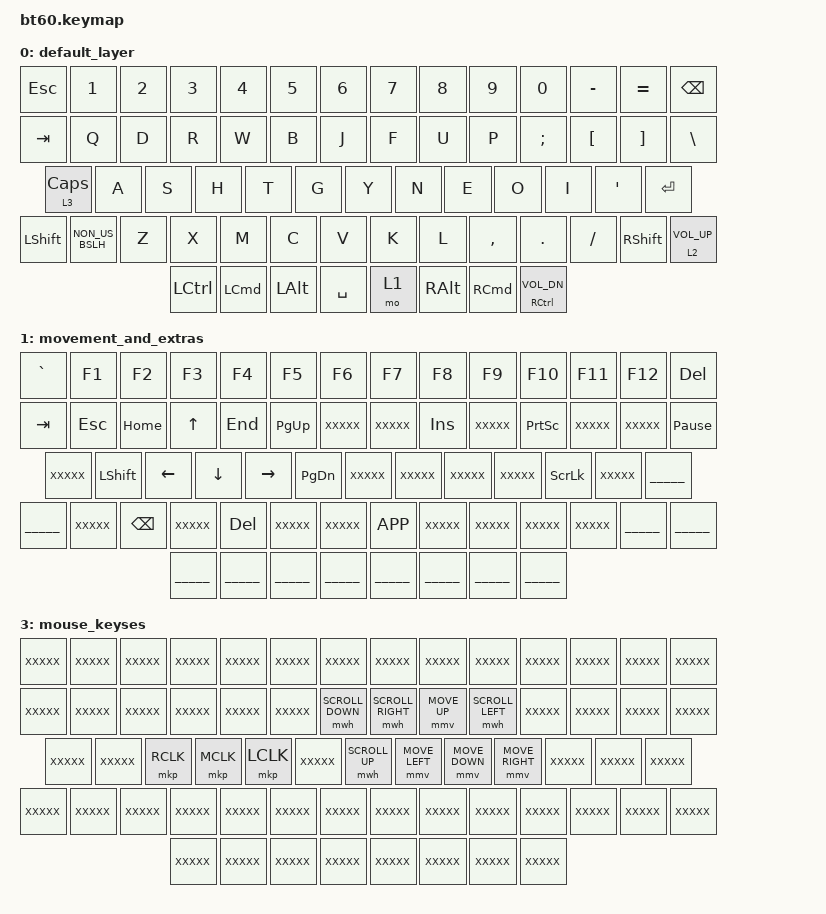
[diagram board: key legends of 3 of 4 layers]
#include <behaviors.dtsi>
#include <dt-bindings/zmk/keys.h>
#include <dt-bindings/zmk/bt.h>
#include <dt-bindings/zmk/rgb.h>
#include <dt-bindings/zmk/backlight.h>
#include <dt-bindings/zmk/mouse.h>																															

#define _____ trans
#define XXXXX none

&mmv {
	time-to-max-speed-ms = <200>;
	acceleration-exponent=<2>;
	
};


/ {
	behaviors {
	           mo_tog: behavior_mo_tog {
          	   	   		    compatible = "zmk,behavior-hold-tap";
            	   			    label = "mo_tog";
		   			    #binding-cells = <2>;
		   			    flavor = "hold-preferred";
		   			    tapping-term-ms = <200>;
		   			    bindings = <&tog>, <&mo>;
	           };
	};
    
	keymap {
		compatible = "zmk,keymap";
				
		default_layer {
		
// Welcome to your layer 0, beebs! The first level, the ground
// floor, the start of the journey! This is where you'll spend most
// of your time. It's set up with Workman by default, and has some
// nice things on it. I've put some spare volume keys at the bottom
// left, but note that holding down the top one (next to your right
// shift) will change to the bluetooth layer. Holding down the L1
// key at the bottom will switch to your second layer.

// ,------------------------------------------------------------.
// |ESC | 1 | 2 | 3 | 4 | 5 | 6 | 7 | 8 | 9 | 0 | - | = |  BKSP |
// |TAB  | Q | D | R | W | B | J | F | U | P | ; | [ | ] |   \\ |
// |CAPS  | A | S | H | T | G | Y | N | E | O | I | ' |   ENTER |
// |SHF|iso| Z | X | M | C | V | K | L | , | . | / | SHIFT |vo↑ |
// |CTRL | CMD | ALT |      SPACE       | L1 | ALT | CTRL | vo↓ |
// '------------------------------------------------------------'

			bindings = <

				&kp ESC                &kp N1 &kp N2 &kp N3 &kp N4 &kp N5 &kp N6 &kp N7 &kp N8    &kp N9  &kp N0   &kp MINUS &kp EQUAL &kp BSPC
				&kp TAB                 &kp Q  &kp D  &kp R  &kp W  &kp B  &kp J  &kp F  &kp U     &kp P   &kp SEMI &kp LBKT  &kp RBKT &kp BSLH
				&lt 3 CAPS                 &kp A  &kp S  &kp H  &kp T  &kp G  &kp Y  &kp N  &kp E     &kp O   &kp I    &kp SQT            &kp RET
				&kp LSHFT &kp NON_US_BSLH &kp Z  &kp X  &kp M  &kp C  &kp V  &kp K  &kp L  &kp COMMA &kp DOT &kp FSLH &kp RSHFT  &lt 2 C_VOL_UP
				&kp LCTRL &kp LCMD &kp LALT            &kp SPACE                       &mo 1 &kp RALT     &kp RCMD     &mt RCTRL C_VOL_DN
			>;
		};

		movement_and_extras {

// This is pretty much everything you're missing from a standard
// keyboard: arrow keys, page navigation, the F-row, escape, delete,
// and the lesser-used keys, like insert, printscreen, pausebreak,
// scroll-lock, and context-menu.

// I've put some extras around, like a backspace on left-ring, an
// extra escape and delete in easier places to reach, and a shift
// key near the arrows for selecting text. I prefer my arrows on the
// right, but it's all your keyboard bb!

// Or maybe you want the arrows on the right, kinda like this?
// |TAB  |ESC|   |   |   |   |PG↑|HOM| ↑ |END|DEL|PRN|   |      |
// |BKSP  |   |   |   |   |   |PG↓| ← | ↓ | → |SHF|   |   ENTER |
// |SHF|   |BRK|   |   |   |   |   |MNU|   |   |   | SHIFT |    |

// The key for this layer could be moved to the left hand so you can
// do your page movement with one hand on the keyboard (if it's
// comfy). Try this, maybe:
// |CTRL | ALT | L1 |      SPACE       | ALT | WIN | CTRL | vo↓ |
// '------------------------------------------------------------'

// ,------------------------------------------------------------.
// |  ` |F1 |F2 |F3 |F4 |F5 |F6 |F7 |F8 |F9 |F10|F11|F12|  DEL  |
// |TAB  |ESC|HOM| ↑ |END|PG↑|   |   |INS|   |PRN|   |   |PAUSEB|
// |      |SHF| ← | ↓ | → |PG↓|   |   |   |   |SLK|   |   ENTER |
// |SHF|   |   |BSP|   |DEL|   |   |MNU|   |   |   | SHIFT |    |
// |CTRL | WIN | ALT |      SPACE       |####| ALT | CTRL |     |
// '------------------------------------------------------------'

			bindings = <

				&kp GRAVE   &kp F1   &kp F2   &kp F3   &kp F4    &kp F5    &kp F6    &kp F7 &kp F8  &kp F9 &kp F10    &kp F11  &kp F12  &kp DEL
				&kp TAB      &kp ESC  &kp HOME &kp UP   &kp END   &kp PG_UP &XXXXX    &XXXXX &kp INS &XXXXX &kp PSCRN  &XXXXX   &XXXXX   &kp PAUSE_BREAK
				&XXXXX       &kp LSHFT   &kp LEFT &kp DOWN &kp RIGHT &kp PG_DN &XXXXX    &XXXXX &XXXXX  &XXXXX &kp SLCK   &XXXXX            &_____
				&_____ &XXXXX&kp BSPC &XXXXX   &kp DEL  &XXXXX    &XXXXX    &kp K_APP &XXXXX &XXXXX  &XXXXX &XXXXX              &_____   &_____
				&_____  &_____ &_____                       &_____                    &_____           &_____        &_____              &_____
			>;
		};

		media_and_kb_settings {
		
// Basically, cutie, this layer has all your experience-related
// things, like changing the bluetooth device, adjusting volume and
// brightness, play/pause/previous/next. If you add more keyboard
// layouts (like QWERTY, Dvorak, etc) then I'd put the keys to
// switch to them on here. It's kinda your "I don't need these much"
// layer.

// ,------------------------------------------------------------. 
// |clr |bt1|bt2|bt3|bt4|bt5|   |   |   |   |   |br-|br+|  BOOT | 14
// |     |   |   |vo↑|   |br↑|   |   |   |   |   |hu-|hu+|  rgb | 14
// |      |   |prv|vo↓|nxt|br↓|   |   |   |   |sa-|sa+|green HSB| 13
// |   |   |   |   |mut|   |   |   |   |   |   |   |       |####| 14
// |     |     |     |        ⏯         |   |     |      |      | 8
// '------------------------------------------------------------'

			bindings = <
				&bt BT_CLR &bt BT_SEL 1 &bt BT_SEL 2 &bt BT_SEL 3 &bt BT_SEL 4 &bt BT_SEL 5 &XXXXX &XXXXX &XXXXX &XXXXX &XXXXX &rgb_ug RGB_BRD &rgb_ug RGB_BRI &bootloader
				&XXXXX      &XXXXX       &XXXXX       &kp C_VOL_UP &XXXXX       &XXXXX       &XXXXX &XXXXX &XXXXX &XXXXX &XXXXX &rgb_ug RGB_HUD &rgb_ug RGB_HUI &rgb_ug RGB_TOG
				&XXXXX       &XXXXX       &kp C_PREV   &kp C_VOL_DN &kp C_NEXT   &XXXXX       &XXXXX &XXXXX &XXXXX &XXXXX &rgb_ug RGB_SAD &rgb_ug RGB_SAI       &rgb_ug RGB_COLOR_HSB(128,100,100)
				&XXXXX &XXXXX &XXXXX       &XXXXX       &kp C_MUTE   &XXXXX       &XXXXX       &XXXXX &XXXXX &XXXXX &XXXXX &XXXXX             &XXXXX &XXXXX
				&XXXXX &XXXXX &XXXXX                        &kp C_PLAY_PAUSE                  &XXXXX        &XXXXX              &XXXXX               &XXXXX
			>;
		};
		
		
	mouse_keyses {
	
// ,------------------------------------------------------------.
// |    |   |   |   |   |   |   |   |   |   |   |   |   |       |
// |     |   |   |   |   |   |UWH|LWH| ↑ |RWH|   |   |   |      |
// | #####|   |rig|mid|lef|   |DWH| ← | ↓ | → |   |   |         |
// |   |   |   |   |   |   |   |   |   |   |   |   |       |    |
// |     |     |     |                  |    |     |      |     |
// '------------------------------------------------------------'

	bindings = <
				&XXXXX &XXXXX &XXXXX &XXXXX &XXXXX &XXXXX &XXXXX &XXXXX &XXXXX &XXXXX &XXXXX &XXXXX &XXXXX &XXXXX
				&XXXXX &XXXXX       &XXXXX       &XXXXX &XXXXX       &XXXXX       &mwh SCROLL_DOWN &mwh SCROLL_RIGHT &mmv MOVE_UP &mwh SCROLL_LEFT &XXXXX &XXXXX &XXXXX &XXXXX
				&XXXXX &XXXXX       &mkp RCLK   &mkp MCLK &mkp LCLK &XXXXX       &mwh SCROLL_UP &mmv MOVE_LEFT &mmv MOVE_DOWN &mmv MOVE_RIGHT &XXXXX &XXXXX       &XXXXX
				&XXXXX &XXXXX &XXXXX       &XXXXX       &XXXXX	&XXXXX       &XXXXX       &XXXXX &XXXXX &XXXXX &XXXXX &XXXXX             &XXXXX &XXXXX
				&XXXXX &XXXXX &XXXXX                        &XXXXX                  &XXXXX        &XXXXX              &XXXXX               &XXXXX
			>;
		};
	};
};

// So yeah, that's your ZMK keyboard firmware configuration!
// You'll probably want to start messing around quick, so you 
// should bookmark the documentation https://zmk.dev/docs

// You don't need to read the whole thing, probably the keycodes
// and RGB underglow sections will be most interesting to you. 
// Why not start by adding some keys to the above layer to 
// change the colours?

// Here's a spare template to copy for making your own cute diagrams
// <3 ilysm and I find it so sexy that you're looking at this xxxx

// ,------------------------------------------------------------.
// |    |   |   |   |   |   |   |   |   |   |   |   |   |       |
// |     |   |   |   |   |   |   |   |   |   |   |   |   |      |
// |      |   |   |   |   |   |   |   |   |   |   |   |         |
// |   |   |   |   |   |   |   |   |   |   |   |   |       |    |
// |     |     |     |                  |    |     |      |     |
// '------------------------------------------------------------'

//	bindings = <
//				&XXXXX &XXXXX &XXXXX &XXXXX &XXXXX &XXXXX &XXXXX &XXXXX &XXXXX &XXXXX &XXXXX &XXXXX &XXXXX &XXXXX
//				&XXXXX &XXXXX       &XXXXX       &XXXXX &XXXXX       &XXXXX       &XXXXX &XXXXX &XXXXX &XXXXX &XXXXX &XXXXX &XXXXX &XXXXX
//				&XXXXX &XXXXX       &XXXXX   &XXXXX &XXXXX &XXXXX       &XXXXX &XXXXX &XXXXX &XXXXX &XXXXX &XXXXX       &XXXXX
//				&XXXXX &XXXXX &XXXXX       &XXXXX       &XXXXX	&XXXXX       &XXXXX       &XXXXX &XXXXX &XXXXX &XXXXX &XXXXX             &XXXXX &XXXXX
//				&XXXXX &XXXXX &XXXXX                        &XXXXX                  &XXXXX        &XXXXX              &XXXXX               &XXXXX
//			>;
